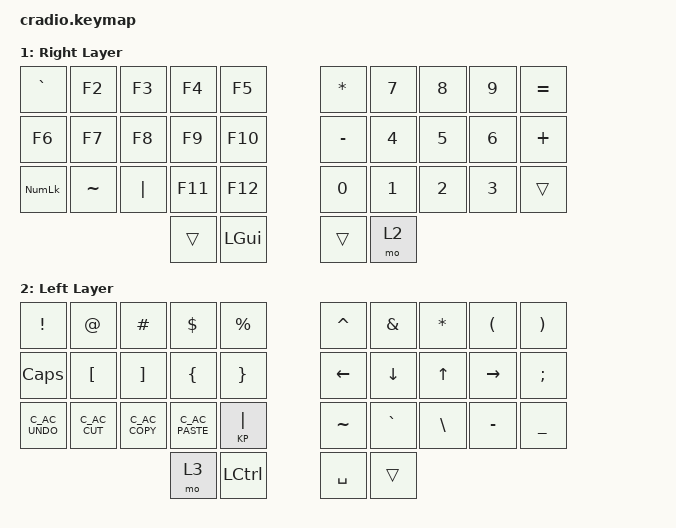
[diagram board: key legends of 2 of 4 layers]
// Copyright (c) 2022 The ZMK Contributors
// SPDX-License-Identifier: MIT

#include <behaviors.dtsi>
#include <dt-bindings/zmk/keys.h>
#include <dt-bindings/zmk/bt.h>

// Home row mods macro
#define HRML(k1,k2,k3,k4) &ht LSHFT k1  &ht LALT k2  &ht LCTRL k3  &ht LGUI k4
#define HRMR(k1,k2,k3,k4) &ht RGUI k1  &ht RCTRL k2  &ht RALT k3  &ht RSHFT k4

/ {
    behaviors {
        ht: hold_tap {
            compatible = "zmk,behavior-hold-tap";
            #binding-cells = <2>;
            flavor = "tap-preferred";
            tapping-term-ms = <125>;
            quick-tap-ms = <95>;
            require-prior-idle-ms = <100>;
            bindings = <&kp>, <&kp>;
        };
    };

    combos {
      compatible = "zmk,combos";
    combo_esc {
        timeout-ms = <50>;
        key-positions = <21 22>;
        bindings = <&kp ESC>;
      };
    combo_tab {
        timeout-ms = <50>;
        key-positions = <0 1>;
        bindings = <&kp TAB>;
      };
    combo_RTAB {
        timeout-ms = <50>;
        key-positions = <17 16>;
        bindings = <&kp TAB>;
      };
    combo_LBSPC {
        timeout-ms = <50>;
        key-positions = <11 12>;
        bindings = <&kp BSPC>;
      };
    combo_LRET {
        timeout-ms = <50>;
        key-positions = <12 13>;
        bindings = <&kp RET>;
      };
    combo_RESC {
        timeout-ms = <50>;
        key-positions = <27 28>;
        bindings = <&kp ESC>;
      };
    combo_ret {
        timeout-ms = <50>;
        key-positions = <18 19>;
        bindings = <&kp RET>;
      };
    combo_bspc {
        timeout-ms = <50>;
        key-positions = <8 9>;
        bindings = <&kp BSPC>;
      };
    };

/*    conditional_layers {
        compatible = "zmk,conditional-layers";
        tri_layer {
            if-layers = <1 2>;
            then-layer = <3>;
        };
    };
*/
    keymap {
        compatible = "zmk,keymap";
        default_layer {
            display-name = "Default Layer";
            bindings = <
        //╭──────────┬──────────┬──────────┬──────────┬──────────╮   ╭──────────┬──────────┬──────────┬──────────┬──────────╮
        //│  Q       │  W       │  E       │  R       │  T       │   │  Y       │  U       │  I       │  O       │  P       │
            &kp Q      &kp W      &kp E      &kp R      &kp T          &kp Y      &kp U      &kp I      &kp O      &kp P
        //├──────────┼──────────┼──────────┼──────────┼──────────┤   ├──────────┼──────────┼──────────┼──────────┼──────────┤
        //│  A       │  S       │  D       │  F       │  G       │   │  H       │  J       │  K       │  L       │ ' "      │
            &kp A     HRML(S,      D,         F,         G)           HRMR(H,      J,         K,         L)        &kp SQT
        //├──────────┼──────────┼──────────┼──────────┼──────────┤   ├──────────┼──────────┼──────────┼──────────┼──────────┤
        //│  Z       │  X       │  C       │  V       │  B       │   │  N       │  M       │ , <      │ . >      │ / ?      │
            &kp Z      &kp X      &kp C      &kp V      &kp B          &kp N      &kp M      &kp COMMA  &kp DOT    &kp FSLH
        //╰──────────┴──────────┴──────────┼──────────┼──────────┤   ├──────────┼──────────┼──────────┴──────────┴──────────╯
                                        &lt 1 SPC   &mt LCTRL ENTER   &lt 1 TAB  &lt 2 BSPC
        //                                 ╰──────────┴──────────╯   ╰──────────┴──────────╯
            >;
        };

        right_layer {
            display-name = "Right Layer";
            bindings = <
        //╭──────────┬──────────┬──────────┬──────────┬──────────╮   ╭──────────┬──────────┬──────────┬──────────┬──────────╮
        //│ INSERT   │  1       │  2       │  3       │          │   │ HOME     │ PAGE DN  │ PAGE UP  │ END      │  :       │
            &kp GRAVE  &kp F2     &kp F3     &kp F4      &kp F5       &kp ASTRK  &kp NUM_7  &kp NUM_8  &kp NUM_9   &kp EQUAL
        //├──────────┼──────────┼──────────┼──────────┼──────────┤   ├──────────┼──────────┼──────────┼──────────┼──────────┤
        //│ DELETE   │  4       │  5       │  6       │          │   │ LEFT     │ DOWN     │ UP       │ RIGHT    │  ;       │
            &kp F6     &kp F7     &kp F8     &kp F9     &kp F10       &kp MINUS  &kp NUM_4  &kp NUM_5  &kp NUM_6   &kp PLUS
        //├──────────┼──────────┼──────────┼──────────┼──────────┤   ├──────────┼──────────┼──────────┼──────────┼──────────┤
        //│ CAPS     │  7       │  8       │  9       │  0       │   │          │          │          │          │          │
           & KP_NLCK   &kp TILDE  &kp PIPE   &kp F11    &kp F12       &kp NUM_0  &kp NUM_1  &kp NUM_2   &kp NUM_3   &trans
        //╰──────────┴──────────┴──────────┼──────────┼──────────┤   ├──────────┼──────────┼──────────┴──────────┴──────────╯
                                             &trans     &kp LGUI        &trans     &mo 2
        //                                 ╰──────────┴──────────╯   ╰──────────┴──────────╯
            >;
        };

        left_layer {
            display-name = "Left Layer";
            bindings = <
        //╭──────────┬──────────┬──────────┬──────────┬──────────╮   ╭──────────┬──────────┬──────────┬──────────┬──────────╮
        //│  !       │  @       │  #       │  $       │  %       │   │  ^       │  &       │  *       │  (       │  )       │
           &kp EXCL   &kp AT     &kp HASH   &kp DLLR   &kp PRCNT      &kp CARET  &kp AMPS   &kp STAR   &kp LPAR   &kp RPAR
        //├──────────┼──────────┼──────────┼──────────┼──────────┤   ├──────────┼──────────┼──────────┼──────────┼──────────┤
        //│  CL      │  [       │  ]       │  {       │  }       │   │  *       │  -       │  =       │  \       │  ;       │
           &kp CAPS   &kp LBKT   &kp RBKT   &kp LBRC   &kp RBRC       &kp LEFT   &kp DOWN   &kp UP     &kp RIGHT   &kp SEMI
        //├──────────┼──────────┼──────────┼──────────┼──────────┤   ├──────────┼──────────┼──────────┼──────────┼──────────┤
        //│          │          │          │          │  |       │   │  &       │  _       │  +       │  │       │          │
          &C_AC_UNDO  &C_AC_CUT &C_AC_COPY &C_AC_PASTE &KP PIPE       &kp TILDE  &kp GRAVE  &kp BSLH   &kp MINUS   &kp UNDER
        //╰──────────┴──────────┴──────────┼──────────┼──────────┤   ├──────────┼──────────┼──────────┴──────────┴──────────╯
                                             &mo 3      &kp LCTL        &kp SPC    &trans
        //                                 ╰──────────┴──────────╯   ╰──────────┴──────────╯
            >;
        };

        tri_layer {
            display-name = "Tri Layer";
            bindings = <
        //╭──────────┬──────────┬──────────┬──────────┬──────────╮   ╭──────────┬──────────┬──────────┬──────────┬──────────╮
        //│ RESET    │          │          │          │PROFILE 0 │   │          │          │          │          │  RESET   │
        &kp C_AC_EXIT &kp C_REPEAT &kp C_PREV &kp C_NEXT &bt BT_PRV  &kp HOME  &kp PG_UP  &kp C_VOL_UP  &C_BRI_UP  &sys_reset
        //├──────────┼──────────┼──────────┼──────────┼──────────┤   ├──────────┼──────────┼──────────┼──────────┼──────────┤
        //│BOOTLOADER│          │          │          │PROFILE 1 │   │          │          │          │          │BOOTLOADER│
         &kp C_AC-STOP &kp C_SNAPSHOT &kp C_RW  &kp C_FF &bt BT_NXT  |  &kp END   &kp PG_DN  &kp C_VOL_DN  &C_BRI_DN  &bootloader
        //├──────────┼──────────┼──────────┼──────────┼──────────┤   ├──────────┼──────────┼──────────┼──────────┼──────────┤
        //│          │          │          │ CLEAR BT │PROFILE 2 │   │          │          │          │          │          │
        &bt BT_CLR &bt BT_SEL 0 &bt BT_SEL 1 &bt BT_SEL 2 &bt BT_SEL 2 &C_AC_BACK  &trans   &kp C_MUTE &C_BRI_AUTO   &trans
        //╰──────────┴──────────┴──────────┼──────────┼──────────┤   ├──────────┼──────────┼──────────┴──────────┴──────────╯
                                             &kp C_PP     &trans         &trans     &trans
        //                                 ╰──────────┴──────────╯   ╰──────────┴──────────╯
            >;
        };
    };
};
